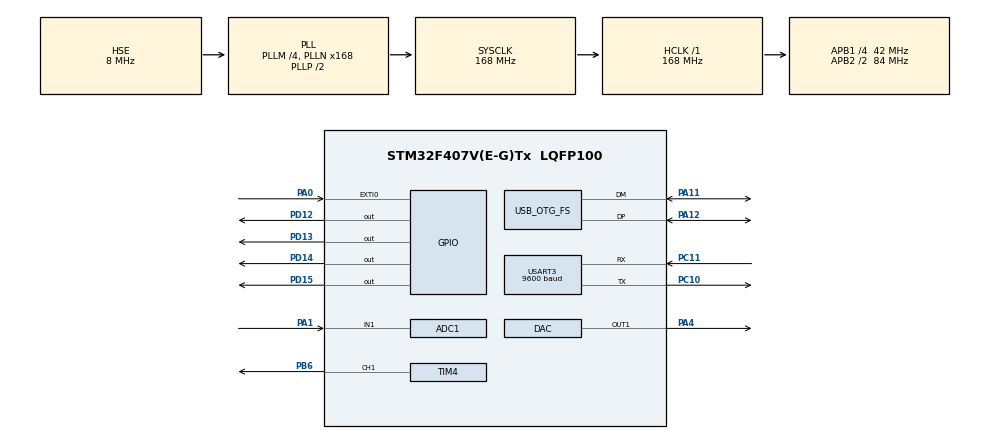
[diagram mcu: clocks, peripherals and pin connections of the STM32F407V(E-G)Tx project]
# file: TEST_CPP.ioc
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ADC1.Channel-0\#ChannelRegularConversion=ADC_CHANNEL_1
ADC1.NbrOfConversionFlag=1
ADC1.Rank-0\#ChannelRegularConversion=1
ADC1.SamplingTime-0\#ChannelRegularConversion=ADC_SAMPLETIME_3CYCLES
ADC1.master=1
Mcu.Family=STM32F4
Mcu.Name=STM32F407V(E-G)Tx
Mcu.Package=LQFP100
NVIC.OTG_FS_IRQn=true\:0\:0\:false\:false\:true\:false\:true
NVIC.PriorityGroup=NVIC_PRIORITYGROUP_4
NVIC.TIM4_IRQn=true\:0\:0\:false\:false\:true\:true\:true
NVIC.USART3_IRQn=true\:0\:0\:false\:false\:true\:true\:true
PA0-WKUP.Signal=GPXTI0
PA1.Signal=ADCx_IN1
PA11.Mode=Device_Only
PA11.Signal=USB_OTG_FS_DM
PA12.Mode=Device_Only
PA12.Signal=USB_OTG_FS_DP
PA4.Signal=COMP_DAC1_group
PB6.Signal=S_TIM4_CH1
PC10.Mode=Asynchronous
PC10.Signal=USART3_TX
PC11.Mode=Asynchronous
PC11.Signal=USART3_RX
PD12.Signal=GPIO_Output
PD13.Signal=GPIO_Output
PD14.Signal=GPIO_Output
PD15.Signal=GPIO_Output
PH0-OSC_IN.Mode=HSE-External-Oscillator
PH0-OSC_IN.Signal=RCC_OSC_IN
PH1-OSC_OUT.Mode=HSE-External-Oscillator
PH1-OSC_OUT.Signal=RCC_OSC_OUT
ProjectManager.HeapSize=0x200
ProjectManager.StackSize=0x400
ProjectManager.TargetToolchain=SW4STM32
RCC.48MHZClocksFreq_Value=48000000
RCC.AHBFreq_Value=168000000
RCC.APB1CLKDivider=RCC_HCLK_DIV4
RCC.APB1Freq_Value=42000000
RCC.APB1TimFreq_Value=84000000
RCC.APB2CLKDivider=RCC_HCLK_DIV2
RCC.APB2Freq_Value=84000000
RCC.APB2TimFreq_Value=168000000
RCC.CortexFreq_Value=168000000
RCC.HCLKFreq_Value=168000000
RCC.HSE_VALUE=8000000
RCC.HSI_VALUE=16000000
RCC.LSE_VALUE=32768
RCC.PLLM=4
RCC.PLLN=168
RCC.PLLQ=7
RCC.SYSCLKFreq_VALUE=168000000
RCC.SYSCLKSource=RCC_SYSCLKSOURCE_PLLCLK
RCC.VCOOutputFreq_Value=336000000
SH.ADCx_IN1.0=ADC1_IN1,IN1
SH.COMP_DAC1_group.0=DAC_OUT1,DAC_OUT1
SH.S_TIM4_CH1.0=TIM4_CH1,PWM Generation1 CH1
TIM4.Channel-PWM\ Generation1\ CH1=TIM_CHANNEL_1
USART3.BaudRate=9600
USART3.VirtualMode=VM_ASYNC
USB_DEVICE.CLASS_NAME_FS=CDC
USB_DEVICE.VirtualMode-CDC_FS=Cdc
USB_DEVICE.VirtualModeFS=Cdc_FS
USB_OTG_FS.VirtualMode=Device_Only
VP_TIM4_VS_ClockSourceINT.Mode=Internal
VP_USB_DEVICE_VS_USB_DEVICE_CDC_FS.Mode=CDC_FS
board=custom

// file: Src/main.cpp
/* USER CODE BEGIN Header */
/**
  ******************************************************************************
  * @file           : main.c
  * @brief          : Main program body
  ******************************************************************************
  ** This notice applies to any and all portions of this file
  * that are not between comment pairs USER CODE BEGIN and
  * USER CODE END. Other portions of this file, whether
  * inserted by the user or by software development tools
  * are owned by their respective copyright owners.
  *
  * COPYRIGHT(c) 2018 STMicroelectronics
  *
  * Redistribution and use in source and binary forms, with or without modification,
  * are permitted provided that the following conditions are met:
  *   1. Redistributions of source code must retain the above copyright notice,
  *      this list of conditions and the following disclaimer.
  *   2. Redistributions in binary form must reproduce the above copyright notice,
  *      this list of conditions and the following disclaimer in the documentation
  *      and/or other materials provided with the distribution.
  *   3. Neither the name of STMicroelectronics nor the names of its contributors
  *      may be used to endorse or promote products derived from this software
  *      without specific prior written permission.
  *
  * THIS SOFTWARE IS PROVIDED BY THE COPYRIGHT HOLDERS AND CONTRIBUTORS "AS IS"
  * AND ANY EXPRESS OR IMPLIED WARRANTIES, INCLUDING, BUT NOT LIMITED TO, THE
  * IMPLIED WARRANTIES OF MERCHANTABILITY AND FITNESS FOR A PARTICULAR PURPOSE ARE
  * DISCLAIMED. IN NO EVENT SHALL THE COPYRIGHT HOLDER OR CONTRIBUTORS BE LIABLE
  * FOR ANY DIRECT, INDIRECT, INCIDENTAL, SPECIAL, EXEMPLARY, OR CONSEQUENTIAL
  * DAMAGES (INCLUDING, BUT NOT LIMITED TO, PROCUREMENT OF SUBSTITUTE GOODS OR
  * SERVICES; LOSS OF USE, DATA, OR PROFITS; OR BUSINESS INTERRUPTION) HOWEVER
  * CAUSED AND ON ANY THEORY OF LIABILITY, WHETHER IN CONTRACT, STRICT LIABILITY,
  * OR TORT (INCLUDING NEGLIGENCE OR OTHERWISE) ARISING IN ANY WAY OUT OF THE USE
  * OF THIS SOFTWARE, EVEN IF ADVISED OF THE POSSIBILITY OF SUCH DAMAGE.
  *
  ******************************************************************************
  */
/* USER CODE END Header */

#include "main.h"
#include "usb_device.h"

/* USER CODE BEGIN Includes */
#include "code.hpp"
/* USER CODE END Includes */

ADC_HandleTypeDef hadc1;

DAC_HandleTypeDef hdac;

TIM_HandleTypeDef htim4;

UART_HandleTypeDef huart3;

void SystemClock_Config(void);
static void MX_GPIO_Init(void);
static void MX_TIM4_Init(void);
static void MX_ADC1_Init(void);
static void MX_DAC_Init(void);
static void MX_USART3_UART_Init(void);

int main(void)
{

  /* MCU Configuration--------------------------------------------------------*/

  /* Reset of all peripherals, Initializes the Flash interface and the Systick. */
  HAL_Init();

  /* USER CODE BEGIN Init */
  code_init(&hadc1, &hdac, &htim4, &huart3);
  /* USER CODE END Init */

  /* Configure the system clock */
  SystemClock_Config();

  /* Initialize all configured peripherals */
  MX_GPIO_Init();
  MX_TIM4_Init();
  MX_ADC1_Init();
  MX_DAC_Init();
  MX_USART3_UART_Init();
  MX_USB_DEVICE_Init();
  /* USER CODE BEGIN 2 */
  code_main_pre_loop();
  /* USER CODE END 2 */

  /* Infinite loop */
  /* USER CODE BEGIN WHILE */
  while (1)
  {
	  code_main_loop();
    /* USER CODE END WHILE */

  }
}

void SystemClock_Config(void)
{
  RCC_OscInitTypeDef RCC_OscInitStruct = {0};
  RCC_ClkInitTypeDef RCC_ClkInitStruct = {0};

  /** Configure the main internal regulator output voltage
  */
  __HAL_RCC_PWR_CLK_ENABLE();
  __HAL_PWR_VOLTAGESCALING_CONFIG(PWR_REGULATOR_VOLTAGE_SCALE1);
  /** Initializes the CPU, AHB and APB busses clocks
  */
  RCC_OscInitStruct.OscillatorType = RCC_OSCILLATORTYPE_HSE;
  RCC_OscInitStruct.HSEState = RCC_HSE_ON;
  RCC_OscInitStruct.PLL.PLLState = RCC_PLL_ON;
  RCC_OscInitStruct.PLL.PLLSource = RCC_PLLSOURCE_HSE;
  RCC_OscInitStruct.PLL.PLLM = 4;
  RCC_OscInitStruct.PLL.PLLN = 168;
  RCC_OscInitStruct.PLL.PLLP = RCC_PLLP_DIV2;
  RCC_OscInitStruct.PLL.PLLQ = 7;
  if (HAL_RCC_OscConfig(&RCC_OscInitStruct) != HAL_OK)
  {
    Error_Handler();
  }
  /** Initializes the CPU, AHB and APB busses clocks
  */
  RCC_ClkInitStruct.ClockType = RCC_CLOCKTYPE_HCLK|RCC_CLOCKTYPE_SYSCLK
                              |RCC_CLOCKTYPE_PCLK1|RCC_CLOCKTYPE_PCLK2;
  RCC_ClkInitStruct.SYSCLKSource = RCC_SYSCLKSOURCE_PLLCLK;
  RCC_ClkInitStruct.AHBCLKDivider = RCC_SYSCLK_DIV1;
  RCC_ClkInitStruct.APB1CLKDivider = RCC_HCLK_DIV4;
  RCC_ClkInitStruct.APB2CLKDivider = RCC_HCLK_DIV2;

  if (HAL_RCC_ClockConfig(&RCC_ClkInitStruct, FLASH_LATENCY_5) != HAL_OK)
  {
    Error_Handler();
  }
}

static void MX_ADC1_Init(void)
{

  ADC_ChannelConfTypeDef sConfig = {0};

  /** Configure the global features of the ADC (Clock, Resolution, Data Alignment and number of conversion)
  */
  hadc1.Instance = ADC1;
  hadc1.Init.ClockPrescaler = ADC_CLOCK_SYNC_PCLK_DIV4;
  hadc1.Init.Resolution = ADC_RESOLUTION_12B;
  hadc1.Init.ScanConvMode = DISABLE;
  hadc1.Init.ContinuousConvMode = DISABLE;
  hadc1.Init.DiscontinuousConvMode = DISABLE;
  hadc1.Init.ExternalTrigConvEdge = ADC_EXTERNALTRIGCONVEDGE_NONE;
  hadc1.Init.ExternalTrigConv = ADC_SOFTWARE_START;
  hadc1.Init.DataAlign = ADC_DATAALIGN_RIGHT;
  hadc1.Init.NbrOfConversion = 1;
  hadc1.Init.DMAContinuousRequests = DISABLE;
  hadc1.Init.EOCSelection = ADC_EOC_SINGLE_CONV;
  if (HAL_ADC_Init(&hadc1) != HAL_OK)
  {
    Error_Handler();
  }
  /** Configure for the selected ADC regular channel its corresponding rank in the sequencer and its sample time.
  */
  sConfig.Channel = ADC_CHANNEL_1;
  sConfig.Rank = 1;
  sConfig.SamplingTime = ADC_SAMPLETIME_3CYCLES;
  if (HAL_ADC_ConfigChannel(&hadc1, &sConfig) != HAL_OK)
  {
    Error_Handler();
  }

}

static void MX_DAC_Init(void)
{

  DAC_ChannelConfTypeDef sConfig = {0};

  /** DAC Initialization
  */
  hdac.Instance = DAC;
  if (HAL_DAC_Init(&hdac) != HAL_OK)
  {
    Error_Handler();
  }
  /** DAC channel OUT1 config
  */
  sConfig.DAC_Trigger = DAC_TRIGGER_NONE;
  sConfig.DAC_OutputBuffer = DAC_OUTPUTBUFFER_ENABLE;
  if (HAL_DAC_ConfigChannel(&hdac, &sConfig, DAC_CHANNEL_1) != HAL_OK)
  {
    Error_Handler();
  }

}

static void MX_TIM4_Init(void)
{

  TIM_ClockConfigTypeDef sClockSourceConfig = {0};
  TIM_MasterConfigTypeDef sMasterConfig = {0};
  TIM_OC_InitTypeDef sConfigOC = {0};

  htim4.Instance = TIM4;
  htim4.Init.Prescaler = 0;
  htim4.Init.CounterMode = TIM_COUNTERMODE_UP;
  htim4.Init.Period = 0;
  htim4.Init.ClockDivision = TIM_CLOCKDIVISION_DIV1;
  htim4.Init.AutoReloadPreload = TIM_AUTORELOAD_PRELOAD_DISABLE;
  if (HAL_TIM_Base_Init(&htim4) != HAL_OK)
  {
    Error_Handler();
  }
  sClockSourceConfig.ClockSource = TIM_CLOCKSOURCE_INTERNAL;
  if (HAL_TIM_ConfigClockSource(&htim4, &sClockSourceConfig) != HAL_OK)
  {
    Error_Handler();
  }
  if (HAL_TIM_PWM_Init(&htim4) != HAL_OK)
  {
    Error_Handler();
  }
  sMasterConfig.MasterOutputTrigger = TIM_TRGO_RESET;
  sMasterConfig.MasterSlaveMode = TIM_MASTERSLAVEMODE_DISABLE;
  if (HAL_TIMEx_MasterConfigSynchronization(&htim4, &sMasterConfig) != HAL_OK)
  {
    Error_Handler();
  }
  sConfigOC.OCMode = TIM_OCMODE_PWM1;
  sConfigOC.Pulse = 0;
  sConfigOC.OCPolarity = TIM_OCPOLARITY_HIGH;
  sConfigOC.OCFastMode = TIM_OCFAST_DISABLE;
  if (HAL_TIM_PWM_ConfigChannel(&htim4, &sConfigOC, TIM_CHANNEL_1) != HAL_OK)
  {
    Error_Handler();
  }
  HAL_TIM_MspPostInit(&htim4);

}

static void MX_USART3_UART_Init(void)
{

  huart3.Instance = USART3;
  huart3.Init.BaudRate = 9600;
  huart3.Init.WordLength = UART_WORDLENGTH_8B;
  huart3.Init.StopBits = UART_STOPBITS_1;
  huart3.Init.Parity = UART_PARITY_NONE;
  huart3.Init.Mode = UART_MODE_TX_RX;
  huart3.Init.HwFlowCtl = UART_HWCONTROL_NONE;
  huart3.Init.OverSampling = UART_OVERSAMPLING_16;
  if (HAL_UART_Init(&huart3) != HAL_OK)
  {
    Error_Handler();
  }

}

static void MX_GPIO_Init(void)
{
  GPIO_InitTypeDef GPIO_InitStruct = {0};

  /* GPIO Ports Clock Enable */
  __HAL_RCC_GPIOH_CLK_ENABLE();
  __HAL_RCC_GPIOA_CLK_ENABLE();
  __HAL_RCC_GPIOD_CLK_ENABLE();
  __HAL_RCC_GPIOC_CLK_ENABLE();
  __HAL_RCC_GPIOB_CLK_ENABLE();

  /*Configure GPIO pin Output Level */
  HAL_GPIO_WritePin(GPIOD, GPIO_PIN_12|GPIO_PIN_13|GPIO_PIN_14|GPIO_PIN_15, GPIO_PIN_RESET);

  /*Configure GPIO pin : PA0 */
  GPIO_InitStruct.Pin = GPIO_PIN_0;
  GPIO_InitStruct.Mode = GPIO_MODE_IT_RISING;
  GPIO_InitStruct.Pull = GPIO_NOPULL;
  HAL_GPIO_Init(GPIOA, &GPIO_InitStruct);

  /*Configure GPIO pins : PD12 PD13 PD14 PD15 */
  GPIO_InitStruct.Pin = GPIO_PIN_12|GPIO_PIN_13|GPIO_PIN_14|GPIO_PIN_15;
  GPIO_InitStruct.Mode = GPIO_MODE_OUTPUT_PP;
  GPIO_InitStruct.Pull = GPIO_NOPULL;
  GPIO_InitStruct.Speed = GPIO_SPEED_FREQ_LOW;
  HAL_GPIO_Init(GPIOD, &GPIO_InitStruct);

}

void Error_Handler(void)
{
}

/************************ (C) COPYRIGHT STMicroelectronics *****END OF FILE****/
